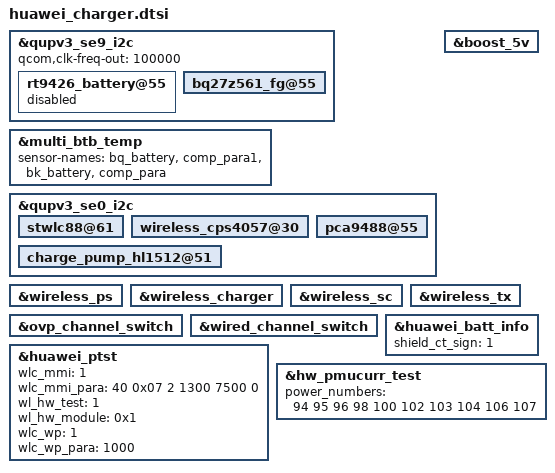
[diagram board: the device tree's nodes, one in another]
&qupv3_se9_i2c {
	qcom,clk-freq-out = <100000>; /* if bq27z561_fg is used, i2c clock must be 100k(100000) */
	rt9426_battery@55{
		status = "disabled";
	};

	bq27z561_fg@55 {
		status = "ok";
	};
};

&multi_btb_temp {
	sensor-names =
		"bq_battery", "comp_para1",
		"bk_battery", "comp_para";
};

&qupv3_se0_i2c {
	stwlc88@61 {
		status = "ok";
	};
	wireless_cps4057@30 {
		status = "ok";
	};
	pca9488@55 {
		status = "ok";
	};
	charge_pump_hl1512@51 {
		status = "ok";
	};
};

&boost_5v {
	status = "ok";
};

&wireless_ps {
	status = "ok";
};

&wireless_charger {
	status = "ok";
};

&wireless_sc {
	status = "ok";
};

&wireless_tx {
	status = "ok";
};

&ovp_channel_switch {
	status = "ok";
};

&wired_channel_switch {
	status = "ok";
};

&huawei_ptst {
	/* definition refered to huawei_power_test.dtsi */
	wlc_mmi = <1>;
	wlc_mmi_para = <40 0x07 2 1300 7500 0>;
	wl_hw_test = <1>;
	wl_hw_module = <0x1>;
	wlc_wp = <1>;
	wlc_wp_para = <1000>;
	status = "ok";
};

&huawei_batt_info {
	status = "ok";
	shield_ct_sign = <1>;
};

&hw_pmucurr_test {
	power_numbers = "94 95 96 98 100 102 103 104 106 107";
};
